VERSION ""

NS_ :

BS_:
BU_: TER_PEDAL ECU_CMDS TER_F_AXLE TER_IMU
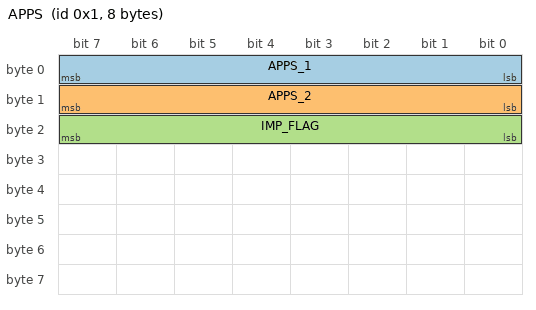
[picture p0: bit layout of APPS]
BO_ 1 APPS: 8 TER_PEDAL
   SG_ APPS_1 : 7|8@0+ (1,0) [0|255] "" Vector__XXX
   SG_ APPS_2 : 15|8@0+ (1,0) [0|255] "" Vector__XXX
   SG_ IMP_FLAG : 23|8@0+ (1,0) [0|255] "" Vector__XXX

BO_ 4 PEDAL_CMD: 8 ECU_CMDS
   SG_ CMD : 7|8@0+ (1,0) [0|1] "" Vector__XXX
   SG_ ARGS : 15|56@0+ (1,0) [0|1] "" Vector__XXX

BO_ 2 BPPS: 1 TER_PEDAL
   SG_ BPPS : 7|8@0+ (1,0) [0|1] "" Vector__XXX

BO_ 5 STEER: 8 TER_PEDAL
   SG_ ANGLE : 7|16@0- (1,0) [-360|360] "Grad" Vector__XXX

BO_ 277 rWheel: 8 TER_F_AXLE
   SG_ RPM : 7|16@0+ (1,0) [0|1] "" Vector__XXX

BO_ 278 lWheel: 8 TER_F_AXLE
   SG_ RPM : 7|16@0+ (1,0) [0|1] "" Vector__XXX

BO_ 42 YPR: 5 TER_IMU
   SG_ YAW m0 : 15|32@2- (1,0) [0|1] "" Vector__XXX
   SG_ PITCH m1 : 15|32@2- (1,0) [0|1] "" Vector__XXX
   SG_ ROLL m2 : 15|32@2- (1,0) [0|1] "" Vector__XXX
   SG_ Yaw_Signal : 7|16@0+ (1,0) [0|1] "" Vector__XXX
   SG_ Pitch_Signal70 : 23|16@0+ (1,0) [0|1] "" Vector__XXX
   SG_ Roll_Signal : 39|16@0+ (1,0) [0|1] "" Vector__XXX

BA_DEF_ BO_ "GenMsgBackgroundColor" STRING ;
BA_DEF_ BO_ "GenMsgForegroundColor" STRING ;
BA_DEF_DEF_ "GenMsgBackgroundColor" "#ffffff";
BA_DEF_DEF_ "GenMsgForegroundColor" "#000000";
=======
BO_ 42 YPR: 8 TER_IMU
   SG_ mux M : 7|8@0+ (1,0) [0|2] "" Vector__XXX
   SG_ YAW m0 : 15|32@2- (1,0) [0|1] "" Vector__XXX
   SG_ PITCH m1 : 15|32@2- (1,0) [0|1] "" Vector__XXX
   SG_ ROLL m2 : 15|32@2- (1,0) [0|1] "" Vector__XXX

BA_DEF_ BO_ "GenMsgBackgroundColor" STRING ;
BA_DEF_ BO_ "GenMsgForegroundColor" STRING ;
BA_DEF_DEF_ "GenMsgBackgroundColor" "#ffffff";
BA_DEF_DEF_ "GenMsgForegroundColor" "#000000";
